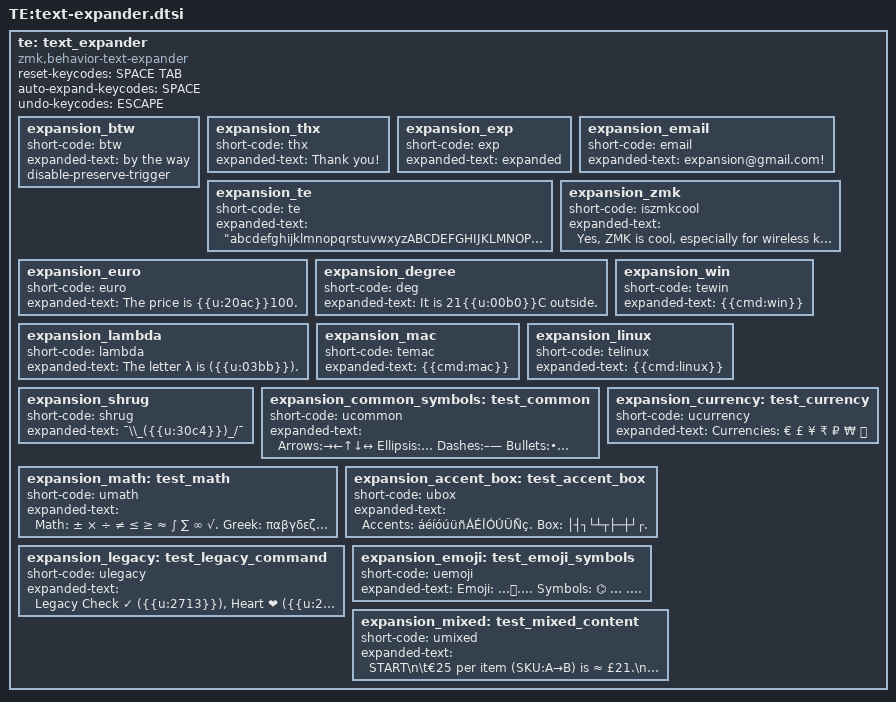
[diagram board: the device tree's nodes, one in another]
te: text_expander {
  compatible = "zmk,behavior-text-expander";
  #binding-cells = <0>;
  reset-keycodes = <SPACE TAB>; 
  auto-expand-keycodes = <SPACE>;
  undo-keycodes = <ESCAPE>;
  expansion_btw {
    short-code = "btw";
    expanded-text = "by the way";
    disable-preserve-trigger;
  };
  expansion_thx {
    short-code = "thx";
    expanded-text = "Thank you!";
  };
  expansion_exp {
    short-code = "exp";
    expanded-text = "expanded";
  };
  expansion_email {
    short-code = "email";
    expanded-text = "expansion@gmail.com!";
  };

  expansion_te {
    short-code = "te";
    expanded-text = "abcdefghijklmnopqrstuvwxyzABCDEFGHIJKLMNOPQRSTUVWXYZ0123456789 .,;:!@#$%^&*()-_=+[]{}\\|'\"`~/?.<>\n\t";
  };

  expansion_zmk {
    short-code = "iszmkcool";
    expanded-text = "Yes, ZMK is cool, especially for wireless keyboards and its rapid development!";
  };

  expansion_euro {
    short-code = "euro";
    expanded-text = "The price is {{u:20ac}}100.";
  };

  expansion_degree {
    short-code = "deg";
    expanded-text = "It is 21{{u:00b0}}C outside.";
  };

  expansion_lambda {
    short-code = "lambda";
    expanded-text = "The letter λ is ({{u:03bb}}).";
  };

  expansion_win {
    short-code = "tewin";
    expanded-text = "{{cmd:win}}";
  };

  expansion_mac {
    short-code = "temac";
    expanded-text = "{{cmd:mac}}";
  };

  expansion_linux {
    short-code = "telinux";
    expanded-text = "{{cmd:linux}}";
  };

  expansion_shrug {
    short-code = "shrug";
    expanded-text = "¯\\_({{u:30c4}})_/¯";
  };


    // 1. Common Symbols and Punctuation
    // Tests a variety of frequently used symbols.
    expansion_common_symbols: test_common {
        short-code = "ucommon";
        expanded-text = "Arrows:→←↑↓↔ Ellipsis:… Dashes:–— Bullets:•· Copyright:©®™";
    };

    // 2. Currency Symbols
    // Tests various multi-byte currency characters from around the world.
    expansion_currency: test_currency {
        short-code = "ucurrency";
        expanded-text = "Currencies: € £ ¥ ₹ ₽ ₩ ₿";
    };

    // 3. Mathematical and Technical Symbols
    // Tests symbols often used in science, math, and engineering.
    expansion_math: test_math {
        short-code = "umath";
        expanded-text = "Math: ± × ÷ ≠ ≤ ≥ ≈ ∫ ∑ ∞ √. Greek: παβγδεζηθ.";
    };

    // 4. Accented Latin Characters & Box Drawing
    // Tests common non-English letters and line-drawing characters.
    expansion_accent_box: test_accent_box {
        short-code = "ubox";
        expanded-text = "Accents: áéíóúüñÁÉÍÓÚÜÑç. Box: │┤┐└┴┬├─┼┘┌.";
    };

    // 5. Backward Compatibility with {{u:XXXX}}
    // Ensures the legacy command format is still parsed correctly.
    expansion_legacy: test_legacy_command {
        short-code = "ulegacy";
        expanded-text = "Legacy Check ✓ ({{u:2713}}), Heart ❤ ({{u:2764}}), Star ★ ({{u:2605}}).";
    };

    // 6. 4-Byte UTF-8 Characters (Emoji and Symbols)
    // This is a crucial test for characters outside the Basic Multilingual Plane (BMP).
    expansion_emoji: test_emoji_symbols {
        short-code = "uemoji";
        expanded-text = "Emoji: 😊👍🚀💡🎉✨🍕. Symbols: ⌬ 🜸 𝄞.";
    };

    // 7. Mixed Content Robustness Test
    // A complex string mixing everything to test the parser thoroughly.
    expansion_mixed: test_mixed_content {
        short-code = "umixed";
        expanded-text = "START\n\t€25 per item (SKU:A→B) is ≈ £21.\n\tFinal check: ✅ ({{u:2705}}).\nEND";
    };
}; 
